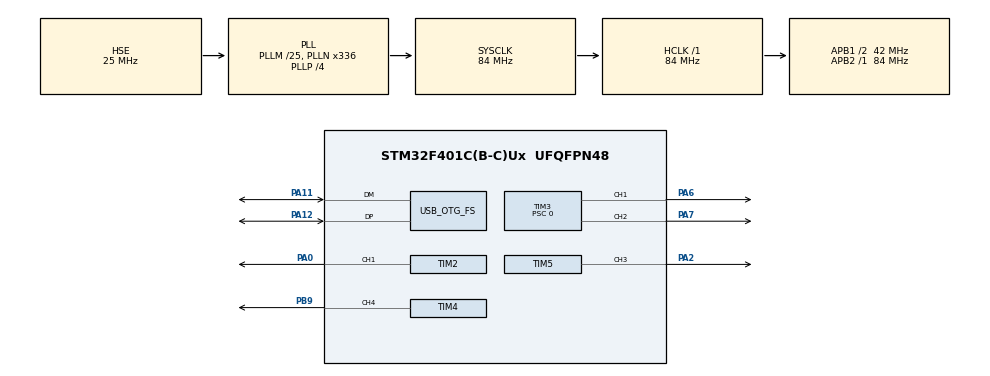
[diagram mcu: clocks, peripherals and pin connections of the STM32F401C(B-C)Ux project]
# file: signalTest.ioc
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Mcu.Family=STM32F4
Mcu.Name=STM32F401C(B-C)Ux
Mcu.Package=UFQFPN48
NVIC.OTG_FS_IRQn=true\:0\:0\:false\:false\:true\:false\:true\:true
NVIC.PriorityGroup=NVIC_PRIORITYGROUP_4
NVIC.TIM2_IRQn=true\:0\:0\:false\:false\:true\:true\:true\:true
NVIC.TIM3_IRQn=true\:0\:0\:false\:false\:true\:true\:true\:true
PA0-WKUP.Signal=S_TIM2_CH1_ETR
PA11.Mode=Device_Only
PA11.Signal=USB_OTG_FS_DM
PA12.Mode=Device_Only
PA12.Signal=USB_OTG_FS_DP
PA2.Signal=S_TIM5_CH3
PA6.Signal=S_TIM3_CH1
PA7.Signal=S_TIM3_CH2
PB9.Signal=S_TIM4_CH4
PH0\ -\ OSC_IN.Mode=HSE-External-Oscillator
PH0\ -\ OSC_IN.Signal=RCC_OSC_IN
PH1\ -\ OSC_OUT.Mode=HSE-External-Oscillator
PH1\ -\ OSC_OUT.Signal=RCC_OSC_OUT
ProjectManager.HeapSize=0x200
ProjectManager.StackSize=0x400
ProjectManager.TargetToolchain=STM32CubeIDE
RCC.48MHZClocksFreq_Value=48000000
RCC.AHBFreq_Value=84000000
RCC.APB1CLKDivider=RCC_HCLK_DIV2
RCC.APB1Freq_Value=42000000
RCC.APB1TimFreq_Value=84000000
RCC.APB2Freq_Value=84000000
RCC.APB2TimFreq_Value=84000000
RCC.CortexFreq_Value=84000000
RCC.HCLKFreq_Value=84000000
RCC.HSE_VALUE=25000000
RCC.HSI_VALUE=16000000
RCC.LSE_VALUE=32768
RCC.PLLM=25
RCC.PLLN=336
RCC.PLLP=RCC_PLLP_DIV4
RCC.PLLQ=7
RCC.SYSCLKFreq_VALUE=84000000
RCC.SYSCLKSource=RCC_SYSCLKSOURCE_PLLCLK
RCC.VCOOutputFreq_Value=336000000
SH.S_TIM2_CH1_ETR.0=TIM2_CH1,PWM Generation1 CH1
SH.S_TIM3_CH1.0=TIM3_CH1,PWM Generation1 CH1
SH.S_TIM3_CH2.0=TIM3_CH2,PWM Generation2 CH2
SH.S_TIM4_CH4.0=TIM4_CH4,PWM Generation4 CH4
SH.S_TIM5_CH3.0=TIM5_CH3,PWM Generation3 CH3
TIM2.Channel-PWM\ Generation1\ CH1=TIM_CHANNEL_1
TIM2.Period=525000-1
TIM2.Pulse-PWM\ Generation1\ CH1=8820-1
TIM2.TIM_MasterOutputTrigger=TIM_TRGO_ENABLE
TIM3.Channel-PWM\ Generation1\ CH1=TIM_CHANNEL_1
TIM3.Channel-PWM\ Generation2\ CH2=TIM_CHANNEL_2
TIM3.Period=168-1
TIM3.Prescaler=0
TIM3.Pulse-PWM\ Generation1\ CH1=84-1
TIM3.Pulse-PWM\ Generation2\ CH2=84-1
TIM4.Channel-PWM\ Generation4\ CH4=TIM_CHANNEL_4
TIM4.Period=168-1
TIM4.Pulse-PWM\ Generation4\ CH4=84-1
TIM4.TIM_MasterSlaveMode=TIM_MASTERSLAVEMODE_DISABLE
TIM5.Channel-PWM\ Generation3\ CH3=TIM_CHANNEL_3
TIM5.Period=840-1
TIM5.Pulse-PWM\ Generation3\ CH3=84-1
TIM5.TIM_MasterOutputTrigger=TIM_TRGO_RESET
TIM5.TIM_MasterSlaveMode=TIM_MASTERSLAVEMODE_ENABLE
USB_DEVICE.CLASS_NAME_FS=CDC
USB_DEVICE.VirtualMode=Cdc
USB_DEVICE.VirtualModeFS=Cdc_FS
USB_OTG_FS.VirtualMode=Device_Only
VP_TIM2_VS_ClockSourceINT.Mode=Internal
VP_TIM3_VS_ClockSourceINT.Mode=Internal
VP_TIM4_VS_ClockSourceINT.Mode=Internal
VP_TIM5_VS_ClockSourceINT.Mode=Internal
VP_TIM5_VS_ClockSourceITR.Mode=TriggerSource_ITR0
VP_TIM5_VS_ControllerModeTrigger.Mode=Trigger Mode
VP_USB_DEVICE_VS_USB_DEVICE_CDC_FS.Mode=CDC_FS
board=custom

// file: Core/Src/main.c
/* USER CODE BEGIN Header */
/**
  ******************************************************************************
  * @file           : main.c
  * @brief          : Main program body
  ******************************************************************************
  * @attention
  *
  * Copyright (c) 2024 STMicroelectronics.
  * All rights reserved.
  *
  * This software is licensed under terms that can be found in the LICENSE file
  * in the root directory of this software component.
  * If no LICENSE file comes with this software, it is provided AS-IS.
  *
  ******************************************************************************
  */
/* USER CODE END Header */
#include "main.h"
#include "usb_device.h"

TIM_HandleTypeDef htim2;
TIM_HandleTypeDef htim3;
TIM_HandleTypeDef htim4;
TIM_HandleTypeDef htim5;

void SystemClock_Config(void);
static void MX_GPIO_Init(void);
static void MX_TIM2_Init(void);
static void MX_TIM3_Init(void);
static void MX_TIM4_Init(void);
static void MX_TIM5_Init(void);

int main(void)
{

  /* MCU Configuration--------------------------------------------------------*/

  /* Reset of all peripherals, Initializes the Flash interface and the Systick. */
  HAL_Init();

  /* Configure the system clock */
  SystemClock_Config();

  /* Initialize all configured peripherals */
  MX_GPIO_Init();
  MX_TIM2_Init();
  MX_TIM3_Init();
  MX_TIM4_Init();
  MX_TIM5_Init();
  MX_USB_DEVICE_Init();
  /* USER CODE BEGIN 2 */
  HAL_TIM_PWM_Start(&htim2, TIM_CHANNEL_1); //ICG
  __HAL_TIM_SET_COUNTER(&htim2, 66);
  HAL_TIM_PWM_Start(&htim3, TIM_CHANNEL_1); //fM
//  HAL_TIM_PWM_Start(&htim4, TIM_CHANNEL_4); //ADC
  HAL_TIM_PWM_Start(&htim5, TIM_CHANNEL_3); //SH

  /* USER CODE END 2 */

  /* Infinite loop */
  /* USER CODE BEGIN WHILE */
  HAL_TIM_Base_Start_IT(&htim2);
  HAL_TIM_Base_Start_IT(&htim3);
  while (1)
  {
    /* USER CODE END WHILE */

  }
}

void SystemClock_Config(void)
{
  RCC_OscInitTypeDef RCC_OscInitStruct = {0};
  RCC_ClkInitTypeDef RCC_ClkInitStruct = {0};

  /** Configure the main internal regulator output voltage
  */
  __HAL_RCC_PWR_CLK_ENABLE();
  __HAL_PWR_VOLTAGESCALING_CONFIG(PWR_REGULATOR_VOLTAGE_SCALE2);

  /** Initializes the RCC Oscillators according to the specified parameters
  * in the RCC_OscInitTypeDef structure.
  */
  RCC_OscInitStruct.OscillatorType = RCC_OSCILLATORTYPE_HSE;
  RCC_OscInitStruct.HSEState = RCC_HSE_ON;
  RCC_OscInitStruct.PLL.PLLState = RCC_PLL_ON;
  RCC_OscInitStruct.PLL.PLLSource = RCC_PLLSOURCE_HSE;
  RCC_OscInitStruct.PLL.PLLM = 25;
  RCC_OscInitStruct.PLL.PLLN = 336;
  RCC_OscInitStruct.PLL.PLLP = RCC_PLLP_DIV4;
  RCC_OscInitStruct.PLL.PLLQ = 7;
  if (HAL_RCC_OscConfig(&RCC_OscInitStruct) != HAL_OK)
  {
    Error_Handler();
  }

  /** Initializes the CPU, AHB and APB buses clocks
  */
  RCC_ClkInitStruct.ClockType = RCC_CLOCKTYPE_HCLK|RCC_CLOCKTYPE_SYSCLK
                              |RCC_CLOCKTYPE_PCLK1|RCC_CLOCKTYPE_PCLK2;
  RCC_ClkInitStruct.SYSCLKSource = RCC_SYSCLKSOURCE_PLLCLK;
  RCC_ClkInitStruct.AHBCLKDivider = RCC_SYSCLK_DIV1;
  RCC_ClkInitStruct.APB1CLKDivider = RCC_HCLK_DIV2;
  RCC_ClkInitStruct.APB2CLKDivider = RCC_HCLK_DIV1;

  if (HAL_RCC_ClockConfig(&RCC_ClkInitStruct, FLASH_LATENCY_2) != HAL_OK)
  {
    Error_Handler();
  }
}

static void MX_TIM2_Init(void)
{

  TIM_ClockConfigTypeDef sClockSourceConfig = {0};
  TIM_MasterConfigTypeDef sMasterConfig = {0};
  TIM_OC_InitTypeDef sConfigOC = {0};

  htim2.Instance = TIM2;
  htim2.Init.Prescaler = 0;
  htim2.Init.CounterMode = TIM_COUNTERMODE_UP;
  htim2.Init.Period = 525000-1;
  htim2.Init.ClockDivision = TIM_CLOCKDIVISION_DIV1;
  htim2.Init.AutoReloadPreload = TIM_AUTORELOAD_PRELOAD_DISABLE;
  if (HAL_TIM_Base_Init(&htim2) != HAL_OK)
  {
    Error_Handler();
  }
  sClockSourceConfig.ClockSource = TIM_CLOCKSOURCE_INTERNAL;
  if (HAL_TIM_ConfigClockSource(&htim2, &sClockSourceConfig) != HAL_OK)
  {
    Error_Handler();
  }
  if (HAL_TIM_PWM_Init(&htim2) != HAL_OK)
  {
    Error_Handler();
  }
  sMasterConfig.MasterOutputTrigger = TIM_TRGO_ENABLE;
  sMasterConfig.MasterSlaveMode = TIM_MASTERSLAVEMODE_DISABLE;
  if (HAL_TIMEx_MasterConfigSynchronization(&htim2, &sMasterConfig) != HAL_OK)
  {
    Error_Handler();
  }
  sConfigOC.OCMode = TIM_OCMODE_PWM1;
  sConfigOC.Pulse = 8820-1;
  sConfigOC.OCPolarity = TIM_OCPOLARITY_HIGH;
  sConfigOC.OCFastMode = TIM_OCFAST_DISABLE;
  if (HAL_TIM_PWM_ConfigChannel(&htim2, &sConfigOC, TIM_CHANNEL_1) != HAL_OK)
  {
    Error_Handler();
  }
  HAL_TIM_MspPostInit(&htim2);

}

static void MX_TIM3_Init(void)
{

  TIM_ClockConfigTypeDef sClockSourceConfig = {0};
  TIM_MasterConfigTypeDef sMasterConfig = {0};
  TIM_OC_InitTypeDef sConfigOC = {0};

  htim3.Instance = TIM3;
  htim3.Init.Prescaler = 0;
  htim3.Init.CounterMode = TIM_COUNTERMODE_UP;
  htim3.Init.Period = 168-1;
  htim3.Init.ClockDivision = TIM_CLOCKDIVISION_DIV1;
  htim3.Init.AutoReloadPreload = TIM_AUTORELOAD_PRELOAD_DISABLE;
  if (HAL_TIM_Base_Init(&htim3) != HAL_OK)
  {
    Error_Handler();
  }
  sClockSourceConfig.ClockSource = TIM_CLOCKSOURCE_INTERNAL;
  if (HAL_TIM_ConfigClockSource(&htim3, &sClockSourceConfig) != HAL_OK)
  {
    Error_Handler();
  }
  if (HAL_TIM_PWM_Init(&htim3) != HAL_OK)
  {
    Error_Handler();
  }
  sMasterConfig.MasterOutputTrigger = TIM_TRGO_RESET;
  sMasterConfig.MasterSlaveMode = TIM_MASTERSLAVEMODE_DISABLE;
  if (HAL_TIMEx_MasterConfigSynchronization(&htim3, &sMasterConfig) != HAL_OK)
  {
    Error_Handler();
  }
  sConfigOC.OCMode = TIM_OCMODE_PWM1;
  sConfigOC.Pulse = 84-1;
  sConfigOC.OCPolarity = TIM_OCPOLARITY_HIGH;
  sConfigOC.OCFastMode = TIM_OCFAST_DISABLE;
  if (HAL_TIM_PWM_ConfigChannel(&htim3, &sConfigOC, TIM_CHANNEL_1) != HAL_OK)
  {
    Error_Handler();
  }
  if (HAL_TIM_PWM_ConfigChannel(&htim3, &sConfigOC, TIM_CHANNEL_2) != HAL_OK)
  {
    Error_Handler();
  }
  HAL_TIM_MspPostInit(&htim3);

}

static void MX_TIM4_Init(void)
{

  TIM_ClockConfigTypeDef sClockSourceConfig = {0};
  TIM_MasterConfigTypeDef sMasterConfig = {0};
  TIM_OC_InitTypeDef sConfigOC = {0};

  htim4.Instance = TIM4;
  htim4.Init.Prescaler = 0;
  htim4.Init.CounterMode = TIM_COUNTERMODE_UP;
  htim4.Init.Period = 168-1;
  htim4.Init.ClockDivision = TIM_CLOCKDIVISION_DIV1;
  htim4.Init.AutoReloadPreload = TIM_AUTORELOAD_PRELOAD_DISABLE;
  if (HAL_TIM_Base_Init(&htim4) != HAL_OK)
  {
    Error_Handler();
  }
  sClockSourceConfig.ClockSource = TIM_CLOCKSOURCE_INTERNAL;
  if (HAL_TIM_ConfigClockSource(&htim4, &sClockSourceConfig) != HAL_OK)
  {
    Error_Handler();
  }
  if (HAL_TIM_PWM_Init(&htim4) != HAL_OK)
  {
    Error_Handler();
  }
  sMasterConfig.MasterOutputTrigger = TIM_TRGO_RESET;
  sMasterConfig.MasterSlaveMode = TIM_MASTERSLAVEMODE_DISABLE;
  if (HAL_TIMEx_MasterConfigSynchronization(&htim4, &sMasterConfig) != HAL_OK)
  {
    Error_Handler();
  }
  sConfigOC.OCMode = TIM_OCMODE_PWM1;
  sConfigOC.Pulse = 84-1;
  sConfigOC.OCPolarity = TIM_OCPOLARITY_HIGH;
  sConfigOC.OCFastMode = TIM_OCFAST_DISABLE;
  if (HAL_TIM_PWM_ConfigChannel(&htim4, &sConfigOC, TIM_CHANNEL_4) != HAL_OK)
  {
    Error_Handler();
  }
  HAL_TIM_MspPostInit(&htim4);

}

static void MX_TIM5_Init(void)
{

  TIM_ClockConfigTypeDef sClockSourceConfig = {0};
  TIM_SlaveConfigTypeDef sSlaveConfig = {0};
  TIM_MasterConfigTypeDef sMasterConfig = {0};
  TIM_OC_InitTypeDef sConfigOC = {0};

  htim5.Instance = TIM5;
  htim5.Init.Prescaler = 0;
  htim5.Init.CounterMode = TIM_COUNTERMODE_UP;
  htim5.Init.Period = 840-1;
  htim5.Init.ClockDivision = TIM_CLOCKDIVISION_DIV1;
  htim5.Init.AutoReloadPreload = TIM_AUTORELOAD_PRELOAD_DISABLE;
  if (HAL_TIM_Base_Init(&htim5) != HAL_OK)
  {
    Error_Handler();
  }
  sClockSourceConfig.ClockSource = TIM_CLOCKSOURCE_INTERNAL;
  if (HAL_TIM_ConfigClockSource(&htim5, &sClockSourceConfig) != HAL_OK)
  {
    Error_Handler();
  }
  if (HAL_TIM_PWM_Init(&htim5) != HAL_OK)
  {
    Error_Handler();
  }
  sSlaveConfig.SlaveMode = TIM_SLAVEMODE_TRIGGER;
  sSlaveConfig.InputTrigger = TIM_TS_ITR0;
  if (HAL_TIM_SlaveConfigSynchro(&htim5, &sSlaveConfig) != HAL_OK)
  {
    Error_Handler();
  }
  sMasterConfig.MasterOutputTrigger = TIM_TRGO_RESET;
  sMasterConfig.MasterSlaveMode = TIM_MASTERSLAVEMODE_ENABLE;
  if (HAL_TIMEx_MasterConfigSynchronization(&htim5, &sMasterConfig) != HAL_OK)
  {
    Error_Handler();
  }
  sConfigOC.OCMode = TIM_OCMODE_PWM1;
  sConfigOC.Pulse = 84-1;
  sConfigOC.OCPolarity = TIM_OCPOLARITY_HIGH;
  sConfigOC.OCFastMode = TIM_OCFAST_DISABLE;
  if (HAL_TIM_PWM_ConfigChannel(&htim5, &sConfigOC, TIM_CHANNEL_3) != HAL_OK)
  {
    Error_Handler();
  }
  HAL_TIM_MspPostInit(&htim5);

}

static void MX_GPIO_Init(void)
{

  /* GPIO Ports Clock Enable */
  __HAL_RCC_GPIOH_CLK_ENABLE();
  __HAL_RCC_GPIOA_CLK_ENABLE();
  __HAL_RCC_GPIOB_CLK_ENABLE();

}

/* USER CODE BEGIN 4 */
uint8_t ICGTriggered = 0;
void HAL_TIM_PeriodElapsedCallback(TIM_HandleTypeDef *htim){
//	we want to start the timer here
	if (htim->Instance == TIM2) {
//		ICGTriggered = 1;
		HAL_TIM_PWM_Start(&htim3, TIM_CHANNEL_2);
		HAL_TIM_PWM_Start(&htim4, TIM_CHANNEL_4);

	}
//	if (htim->Instance == TIM3) {
//	        // Start Timer 4 PWM on Channel 4
//		if(ICGTriggered)
//	        HAL_TIM_PWM_Start(&htim4, TIM_CHANNEL_4);
//	}

}

/* USER CODE END 4 */

void Error_Handler(void)
{
  __disable_irq();
  while (1)
  {
  }
}
